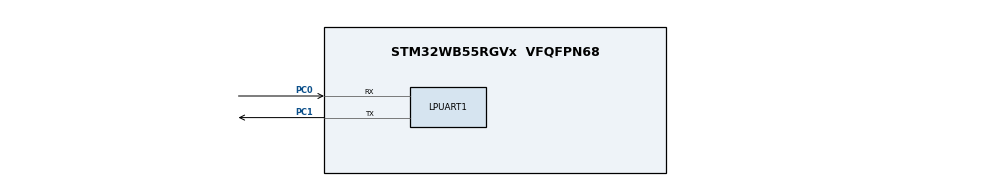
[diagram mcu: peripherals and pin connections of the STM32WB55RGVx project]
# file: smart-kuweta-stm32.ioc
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FREERTOS.Tasks01=defaultTask,24,128,StartDefaultTask,Default,NULL,Dynamic,NULL,NULL
Mcu.Family=STM32WB
Mcu.Name=STM32WB55RGVx
Mcu.Package=VFQFPN68
NVIC.EXTI0_IRQn=true\:5\:0\:false\:false\:true\:true\:false\:true\:true
NVIC.EXTI1_IRQn=true\:5\:0\:false\:false\:true\:true\:false\:true\:true
NVIC.EXTI4_IRQn=true\:5\:0\:false\:false\:true\:true\:false\:true\:true
NVIC.PriorityGroup=NVIC_PRIORITYGROUP_4
OSC_IN.GPIO_Label=RCC_OSC_IN
OSC_IN.Signal=RCC_OSC_IN
OSC_OUT.GPIO_Label=RCC_OSC_OUT
OSC_OUT.Signal=RCC_OSC_OUT
P-NUCLEO-WB55-NUCLEO.BUTTON=1
P-NUCLEO-WB55-NUCLEO.BUTTON2=1
P-NUCLEO-WB55-NUCLEO.BUTTON3=1
P-NUCLEO-WB55-NUCLEO.LD1=true
P-NUCLEO-WB55-NUCLEO.LD2=true
P-NUCLEO-WB55-NUCLEO.LD3=true
P-NUCLEO-WB55-NUCLEO.VCP=true
PA11.GPIO_Label=USB_DM
PA11.Signal=USB_DM
PA12.GPIO_Label=USB_DP
PA12.Signal=USB_DP
PA13.GPIO_Label=JTMS
PA13.Signal=SYS_JTMS-SWDIO
PA14.GPIO_Label=JTCK
PA14.Signal=SYS_JTCK-SWCLK
PB3.GPIO_Label=JTDO
PB3.Signal=SYS_JTDO-SWO
PB6.Signal=USART1_TX
PB7.Signal=USART1_RX
PC0.Mode=Asynchronous
PC0.Signal=LPUART1_RX
PC1.Mode=Asynchronous
PC1.Signal=LPUART1_TX
PC13.GPIO_Label=SYS_WKUP2
PC13.Signal=SYS_WKUP2
PC14-OSC32_IN.GPIO_Label=RCC_OSC32_IN
PC14-OSC32_IN.Signal=RCC_OSC32_IN
PC15-OSC32_OUT.GPIO_Label=RCC_OSC32_OUT
PC15-OSC32_OUT.Signal=RCC_OSC32_OUT
ProjectManager.HeapSize=0x200
ProjectManager.StackSize=0x400
ProjectManager.TargetToolchain=STM32CubeIDE
RCC.ADCFreq_Value=128000000
RCC.AHBFreq_Value=32000000
RCC.APB1Freq_Value=32000000
RCC.APB1TimFreq_Value=32000000
RCC.APB2Freq_Value=32000000
RCC.APB2TimFreq_Value=32000000
RCC.APB3Freq_Value=16000000
RCC.CortexFreq_Value=32000000
RCC.HCLKFreq_Value=32000000
RCC.HSE_VALUE=32000000
RCC.HSI48_VALUE=48000000
RCC.HSI_VALUE=16000000
RCC.LSE_VALUE=32768
RCC.MSIClockRange=RCC_MSIRANGE_10
RCC.SMPSCLockSelection=RCC_SMPSCLKSOURCE_HSI
RCC.SMPSCLockSelectionVirtual=RCC_SMPSCLKSOURCE_HSI
RCC.SMPSCLockSelectionVirtualVirtual=RCC_SMPSCLKSOURCE_HSI
RCC.SMPSDivider=1
RCC.SYSCLKFreq_VALUE=32000000
RCC.USBFreq_Value=128000000
RCC.VCOOutputFreq_Value=256000000
VP_FREERTOS_VS_CMSIS_V2.Mode=CMSIS_V2
VP_MEMORYMAP_VS_MEMORYMAP.Mode=CurAppReg
VP_P-NUCLEO-WB55-NUCLEO_VS_BSP_COMMON.Mode=COMMON
board=P-NUCLEO-WB55-NUCLEO

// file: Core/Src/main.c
/* USER CODE BEGIN Header */
/**
  ******************************************************************************
  * @file           : main.c
  * @brief          : Main program body
  ******************************************************************************
  * @attention
  *
  * Copyright (c) 2026 STMicroelectronics.
  * All rights reserved.
  *
  * This software is licensed under terms that can be found in the LICENSE file
  * in the root directory of this software component.
  * If no LICENSE file comes with this software, it is provided AS-IS.
  *
  ******************************************************************************
  */
/* USER CODE END Header */
#include "main.h"
#include "cmsis_os2.h"
#include "FreeRTOS.h"

/* USER CODE BEGIN PTD */
typedef enum {
    PIR_IDLE,
    PIR_VALIDATING,
    PIR_MEASURING,
} PirState_t;
/* USER CODE END PTD */

/* USER CODE BEGIN PD */
#define PIR_MIN_PULSES   3U
#define PIR_TIMEOUT_MS   5000U
#define PIR_POLL_MS      100U
/* USER CODE END PD */

COM_InitTypeDef BspCOMInit;
UART_HandleTypeDef hlpuart1;

/* Definitions for defaultTask */
osThreadId_t defaultTaskHandle;
const osThreadAttr_t defaultTask_attributes = {
  .name = "defaultTask",
  .priority = (osPriority_t) osPriorityNormal,
  .stack_size = 512 * 4
};
/* USER CODE BEGIN PV */
volatile uint32_t last_visit_duration_ms = 0;
/* USER CODE END PV */

void SystemClock_Config(void);
void PeriphCommonClock_Config(void);
static void MX_GPIO_Init(void);
static void MX_LPUART1_UART_Init(void);
void StartDefaultTask(void *argument);

/* USER CODE BEGIN PFP */
static void send_visit_uart(uint32_t duration_ms);

/* USER CODE END PFP */

int main(void)
{

  /* MCU Configuration--------------------------------------------------------*/

  /* Reset of all peripherals, Initializes the Flash interface and the Systick. */
  HAL_Init();

  /* Configure the system clock */
  SystemClock_Config();

  /* Configure the peripherals common clocks */
  PeriphCommonClock_Config();

  /* Initialize all configured peripherals */
  MX_GPIO_Init();
  MX_LPUART1_UART_Init();

  /* Init scheduler */
  osKernelInitialize();

  /* Create the thread(s) */
  /* creation of defaultTask */
  defaultTaskHandle = osThreadNew(StartDefaultTask, NULL, &defaultTask_attributes);

  /* Initialize leds */
  BSP_LED_Init(LED_BLUE);
  BSP_LED_Init(LED_GREEN);
  BSP_LED_Init(LED_RED);

  /* Initialize USER push-button, will be used to trigger an interrupt each time it's pressed.*/
  BSP_PB_Init(BUTTON_SW1, BUTTON_MODE_EXTI);
  BSP_PB_Init(BUTTON_SW2, BUTTON_MODE_EXTI);
  BSP_PB_Init(BUTTON_SW3, BUTTON_MODE_EXTI);

  /* Initialize COM1 port (115200, 8 bits (7-bit data + 1 stop bit), no parity */
  BspCOMInit.BaudRate   = 115200;
  BspCOMInit.WordLength = COM_WORDLENGTH_8B;
  BspCOMInit.StopBits   = COM_STOPBITS_1;
  BspCOMInit.Parity     = COM_PARITY_NONE;
  BspCOMInit.HwFlowCtl  = COM_HWCONTROL_NONE;
  if (BSP_COM_Init(COM1, &BspCOMInit) != BSP_ERROR_NONE)
  {
    Error_Handler();
  }

  /* Start scheduler */
  osKernelStart();

  /* We should never get here as control is now taken by the scheduler */

  /* Infinite loop */
  while (1)
  {

  }
}

void SystemClock_Config(void)
{
  RCC_OscInitTypeDef RCC_OscInitStruct = {0};
  RCC_ClkInitTypeDef RCC_ClkInitStruct = {0};

  /** Configure the main internal regulator output voltage
  */
  __HAL_PWR_VOLTAGESCALING_CONFIG(PWR_REGULATOR_VOLTAGE_SCALE1);

  /** Initializes the RCC Oscillators according to the specified parameters
  * in the RCC_OscInitTypeDef structure.
  */
  RCC_OscInitStruct.OscillatorType = RCC_OSCILLATORTYPE_HSI|RCC_OSCILLATORTYPE_MSI;
  RCC_OscInitStruct.HSIState = RCC_HSI_ON;
  RCC_OscInitStruct.MSIState = RCC_MSI_ON;
  RCC_OscInitStruct.HSICalibrationValue = RCC_HSICALIBRATION_DEFAULT;
  RCC_OscInitStruct.MSICalibrationValue = RCC_MSICALIBRATION_DEFAULT;
  RCC_OscInitStruct.MSIClockRange = RCC_MSIRANGE_10;
  RCC_OscInitStruct.PLL.PLLState = RCC_PLL_NONE;
  if (HAL_RCC_OscConfig(&RCC_OscInitStruct) != HAL_OK)
  {
    Error_Handler();
  }

  /** Configure the SYSCLKSource, HCLK, PCLK1 and PCLK2 clocks dividers
  */
  RCC_ClkInitStruct.ClockType = RCC_CLOCKTYPE_HCLK4|RCC_CLOCKTYPE_HCLK2
                              |RCC_CLOCKTYPE_HCLK|RCC_CLOCKTYPE_SYSCLK
                              |RCC_CLOCKTYPE_PCLK1|RCC_CLOCKTYPE_PCLK2;
  RCC_ClkInitStruct.SYSCLKSource = RCC_SYSCLKSOURCE_MSI;
  RCC_ClkInitStruct.AHBCLKDivider = RCC_SYSCLK_DIV1;
  RCC_ClkInitStruct.APB1CLKDivider = RCC_HCLK_DIV1;
  RCC_ClkInitStruct.APB2CLKDivider = RCC_HCLK_DIV1;
  RCC_ClkInitStruct.AHBCLK2Divider = RCC_SYSCLK_DIV1;
  RCC_ClkInitStruct.AHBCLK4Divider = RCC_SYSCLK_DIV1;

  if (HAL_RCC_ClockConfig(&RCC_ClkInitStruct, FLASH_LATENCY_1) != HAL_OK)
  {
    Error_Handler();
  }
}

void PeriphCommonClock_Config(void)
{
  RCC_PeriphCLKInitTypeDef PeriphClkInitStruct = {0};

  /** Initializes the peripherals clock
  */
  PeriphClkInitStruct.PeriphClockSelection = RCC_PERIPHCLK_SMPS;
  PeriphClkInitStruct.SmpsClockSelection = RCC_SMPSCLKSOURCE_HSI;
  PeriphClkInitStruct.SmpsDivSelection = RCC_SMPSCLKDIV_RANGE0;

  if (HAL_RCCEx_PeriphCLKConfig(&PeriphClkInitStruct) != HAL_OK)
  {
    Error_Handler();
  }
}

static void MX_LPUART1_UART_Init(void)
{

  hlpuart1.Instance = LPUART1;
  hlpuart1.Init.BaudRate = 115200;
  hlpuart1.Init.WordLength = UART_WORDLENGTH_8B;
  hlpuart1.Init.StopBits = UART_STOPBITS_1;
  hlpuart1.Init.Parity = UART_PARITY_NONE;
  hlpuart1.Init.Mode = UART_MODE_TX_RX;
  hlpuart1.Init.HwFlowCtl = UART_HWCONTROL_NONE;
  hlpuart1.Init.OneBitSampling = UART_ONE_BIT_SAMPLE_DISABLE;
  hlpuart1.Init.ClockPrescaler = UART_PRESCALER_DIV1;
  hlpuart1.AdvancedInit.AdvFeatureInit = UART_ADVFEATURE_NO_INIT;
  hlpuart1.FifoMode = UART_FIFOMODE_DISABLE;
  if (HAL_UART_Init(&hlpuart1) != HAL_OK)
  {
    Error_Handler();
  }
  if (HAL_UARTEx_SetTxFifoThreshold(&hlpuart1, UART_TXFIFO_THRESHOLD_1_8) != HAL_OK)
  {
    Error_Handler();
  }
  if (HAL_UARTEx_SetRxFifoThreshold(&hlpuart1, UART_RXFIFO_THRESHOLD_1_8) != HAL_OK)
  {
    Error_Handler();
  }
  if (HAL_UARTEx_DisableFifoMode(&hlpuart1) != HAL_OK)
  {
    Error_Handler();
  }

}

static void MX_GPIO_Init(void)
{
  GPIO_InitTypeDef GPIO_InitStruct = {0};

  /* GPIO Ports Clock Enable */
  __HAL_RCC_GPIOC_CLK_ENABLE();
  __HAL_RCC_GPIOA_CLK_ENABLE();
  __HAL_RCC_GPIOB_CLK_ENABLE();

  /*Configure GPIO pins : USB_DM_Pin USB_DP_Pin */
  GPIO_InitStruct.Pin = USB_DM_Pin|USB_DP_Pin;
  GPIO_InitStruct.Mode = GPIO_MODE_AF_PP;
  GPIO_InitStruct.Pull = GPIO_NOPULL;
  GPIO_InitStruct.Speed = GPIO_SPEED_FREQ_LOW;
  GPIO_InitStruct.Alternate = GPIO_AF10_USB;
  HAL_GPIO_Init(GPIOA, &GPIO_InitStruct);

  /* USER CODE BEGIN MX_GPIO_Init_2 */

  /* PIR HC-SR501 on PB2 — active-high digital output */
  GPIO_InitStruct.Pin = PIR_Pin;
  GPIO_InitStruct.Mode = GPIO_MODE_INPUT;
  GPIO_InitStruct.Pull = GPIO_PULLDOWN;
  HAL_GPIO_Init(PIR_GPIO_Port, &GPIO_InitStruct);

  /* USER CODE END MX_GPIO_Init_2 */
}

/* USER CODE BEGIN 4 */
static void send_visit_uart(uint32_t duration_ms)
{
    char buf[64];
    int len = snprintf(buf, sizeof(buf),
                       "{\"duration_s\": %lu, \"event\": \"visit_end\"}\n",
                       duration_ms / 1000UL);
    if (len > 0)
        HAL_UART_Transmit(&hlpuart1, (uint8_t *)buf, (uint16_t)len, 200);
}
/* USER CODE END 4 */

void StartDefaultTask(void *argument)
{
  /* USER CODE BEGIN 5 */
  PirState_t state = PIR_IDLE;
  GPIO_PinState prev_pin = GPIO_PIN_RESET;
  uint32_t start_tick = 0;
  uint32_t last_high_tick = 0;
  uint32_t pulse_count = 0;

  for(;;)
  {
    GPIO_PinState pin = HAL_GPIO_ReadPin(PIR_GPIO_Port, PIR_Pin);
    uint32_t now = osKernelGetTickCount();
    int rising_edge = (pin == GPIO_PIN_SET) && (prev_pin == GPIO_PIN_RESET);

    switch (state)
    {
      case PIR_IDLE:
        BSP_LED_Off(LED_BLUE);
        BSP_LED_Off(LED_GREEN);
        if (rising_edge)
        {
          pulse_count = 1;
          start_tick = now;
          last_high_tick = now;
          state = PIR_VALIDATING;
        }
        break;

      case PIR_VALIDATING:
        if (pin == GPIO_PIN_SET)
        {
          BSP_LED_On(LED_BLUE);
          last_high_tick = now;
        }
        else
        {
          BSP_LED_Off(LED_BLUE);
        }
        if (rising_edge)
        {
          pulse_count++;
          if (pulse_count >= PIR_MIN_PULSES)
          {
            state = PIR_MEASURING;
            BSP_LED_On(LED_GREEN);
          }
        }
        /* No HIGH for 5 s before reaching 3 pulses — cancel */
        if ((now - last_high_tick) >= PIR_TIMEOUT_MS)
        {
          state = PIR_IDLE;
          pulse_count = 0;
        }
        break;

      case PIR_MEASURING:
        if (pin == GPIO_PIN_SET)
        {
          BSP_LED_On(LED_BLUE);
          last_high_tick = now;
        }
        else
        {
          BSP_LED_Off(LED_BLUE);
        }
        /* 5 s gap with no HIGH — visit is over */
        if ((now - last_high_tick) >= PIR_TIMEOUT_MS)
        {
          uint32_t raw = now - start_tick;
          last_visit_duration_ms = (raw >= PIR_TIMEOUT_MS) ? (raw - PIR_TIMEOUT_MS) : 0;
          send_visit_uart(last_visit_duration_ms);
          state = PIR_IDLE;
          pulse_count = 0;
          BSP_LED_Off(LED_GREEN);
        }
        break;
    }

    prev_pin = pin;
    osDelay(PIR_POLL_MS);
  }
  /* USER CODE END 5 */
}

void Error_Handler(void)
{
  __disable_irq();
  while (1)
  {
  }
}
